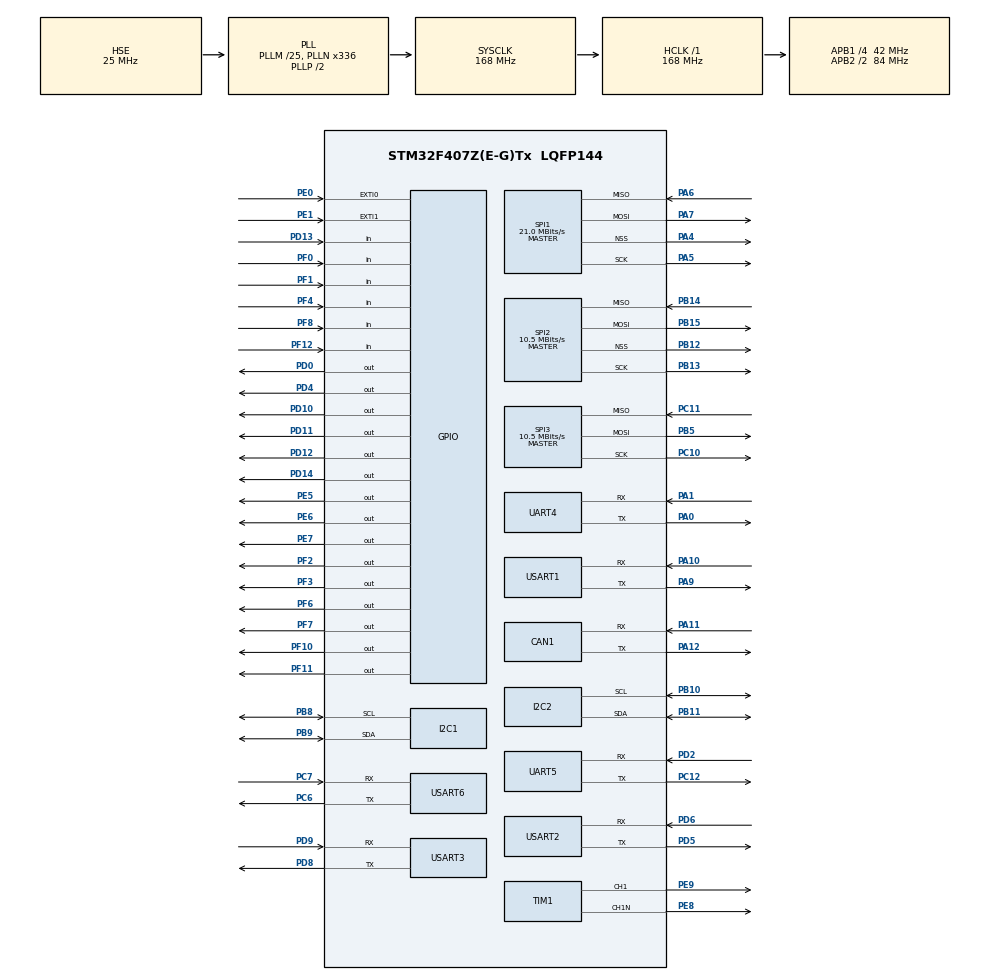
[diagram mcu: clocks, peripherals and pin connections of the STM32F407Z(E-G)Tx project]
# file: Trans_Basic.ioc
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CAN1.ABOM=ENABLE
CAN1.AWUM=ENABLE
CAN1.BS1=CAN_BS1_8TQ
CAN1.BS2=CAN_BS2_6TQ
CAN1.CalculateTimeQuantum=380.95238095238096
Dma.Request0=USART2_TX
Dma.USART2_TX.0.Direction=DMA_MEMORY_TO_PERIPH
Dma.USART2_TX.0.FIFOMode=DMA_FIFOMODE_DISABLE
Dma.USART2_TX.0.Instance=DMA1_Stream6
Dma.USART2_TX.0.MemDataAlignment=DMA_MDATAALIGN_BYTE
Dma.USART2_TX.0.MemInc=DMA_MINC_ENABLE
Dma.USART2_TX.0.Mode=DMA_NORMAL
Dma.USART2_TX.0.PeriphDataAlignment=DMA_PDATAALIGN_BYTE
Dma.USART2_TX.0.PeriphInc=DMA_PINC_DISABLE
Dma.USART2_TX.0.Priority=DMA_PRIORITY_LOW
I2C1.I2C_Mode=I2C_Fast
I2C1.OwnAddress=0x0A
I2C2.I2C_Mode=I2C_Fast
I2C2.OwnAddress=0x0A
Mcu.Family=STM32F4
Mcu.Name=STM32F407Z(E-G)Tx
Mcu.Package=LQFP144
NVIC.CAN1_RX0_IRQn=true\:2\:0\:true\:false\:true\:true
NVIC.DMA1_Stream6_IRQn=true\:0\:0\:false\:false\:true\:false
NVIC.EXTI0_IRQn=true\:0\:0\:false\:false\:true\:true
NVIC.EXTI1_IRQn=true\:0\:0\:false\:false\:true\:true
NVIC.PriorityGroup=NVIC_PRIORITYGROUP_4
NVIC.SPI1_IRQn=true\:1\:0\:true\:false\:true\:true
NVIC.SPI2_IRQn=true\:1\:0\:true\:false\:true\:true
NVIC.UART4_IRQn=true\:2\:0\:true\:false\:true\:true
NVIC.UART5_IRQn=true\:1\:0\:true\:false\:true\:true
NVIC.USART1_IRQn=true\:2\:0\:true\:false\:true\:true
NVIC.USART2_IRQn=true\:1\:0\:true\:false\:true\:true
NVIC.USART3_IRQn=true\:2\:0\:true\:false\:true\:true
PA0-WKUP.Mode=Asynchronous
PA0-WKUP.Signal=UART4_TX
PA1.Mode=Asynchronous
PA1.Signal=UART4_RX
PA10.Mode=Asynchronous
PA10.Signal=USART1_RX
PA11.Mode=Master
PA11.Signal=CAN1_RX
PA12.Mode=Master
PA12.Signal=CAN1_TX
PA13.Mode=JTAG_5_pins
PA13.Signal=SYS_JTMS-SWDIO
PA14.Mode=JTAG_5_pins
PA14.Signal=SYS_JTCK-SWCLK
PA15.Mode=JTAG_5_pins
PA15.Signal=SYS_JTDI
PA4.Mode=NSS_Signal_Hard_Output
PA4.Signal=SPI1_NSS
PA5.Mode=Full_Duplex_Master
PA5.Signal=SPI1_SCK
PA6.Mode=Full_Duplex_Master
PA6.Signal=SPI1_MISO
PA7.Mode=Full_Duplex_Master
PA7.Signal=SPI1_MOSI
PA9.Mode=Asynchronous
PA9.Signal=USART1_TX
PB10.Mode=I2C
PB10.Signal=I2C2_SCL
PB11.Mode=I2C
PB11.Signal=I2C2_SDA
PB12.Mode=NSS_Signal_Hard_Output
PB12.Signal=SPI2_NSS
PB13.Mode=Full_Duplex_Master
PB13.Signal=SPI2_SCK
PB14.Mode=Full_Duplex_Master
PB14.Signal=SPI2_MISO
PB15.Mode=Full_Duplex_Master
PB15.Signal=SPI2_MOSI
PB3.Mode=JTAG_5_pins
PB3.Signal=SYS_JTDO-SWO
PB4.Mode=JTAG_5_pins
PB4.Signal=SYS_JTRST
PB5.Mode=Full_Duplex_Master
PB5.Signal=SPI3_MOSI
PB8.Mode=I2C
PB8.Signal=I2C1_SCL
PB9.Mode=I2C
PB9.Signal=I2C1_SDA
PC10.Mode=Full_Duplex_Master
PC10.Signal=SPI3_SCK
PC11.Mode=Full_Duplex_Master
PC11.Signal=SPI3_MISO
PC12.Mode=Asynchronous
PC12.Signal=UART5_TX
PC6.Mode=Asynchronous
PC6.Signal=USART6_TX
PC7.Mode=Asynchronous
PC7.Signal=USART6_RX
PD0.GPIO_ModeDefaultOutputPP=GPIO_MODE_OUTPUT_PP
PD0.GPIO_PuPd=GPIO_NOPULL
PD0.GPIO_Speed=GPIO_SPEED_FREQ_LOW
PD0.PinState=GPIO_PIN_RESET
PD0.Signal=GPIO_Output
PD10.GPIO_Speed=GPIO_SPEED_FREQ_HIGH
PD10.Signal=GPIO_Output
PD11.PinState=GPIO_PIN_SET
PD11.Signal=GPIO_Output
PD12.PinState=GPIO_PIN_SET
PD12.Signal=GPIO_Output
PD13.GPIO_PuPd=GPIO_PULLUP
PD13.Signal=GPIO_Input
PD14.GPIO_PuPd=GPIO_NOPULL
PD14.Signal=GPIO_Output
PD2.Mode=Asynchronous
PD2.Signal=UART5_RX
PD4.Signal=GPIO_Output
PD5.Mode=Asynchronous
PD5.Signal=USART2_TX
PD6.Mode=Asynchronous
PD6.Signal=USART2_RX
PD8.Mode=Asynchronous
PD8.Signal=USART3_TX
PD9.Mode=Asynchronous
PD9.Signal=USART3_RX
PE0.Signal=GPXTI0
PE1.Signal=GPXTI1
PE5.GPIO_Speed=GPIO_SPEED_FREQ_HIGH
PE5.Signal=GPIO_Output
PE6.GPIO_Speed=GPIO_SPEED_FREQ_HIGH
PE6.Signal=GPIO_Output
PE7.Signal=GPIO_Output
PE8.Mode=PWM Generation1 CH1 CH1N
PE8.Signal=TIM1_CH1N
PE9.Signal=S_TIM1_CH1
PF0.GPIO_PuPd=GPIO_NOPULL
PF0.Signal=GPIO_Input
PF1.GPIO_PuPd=GPIO_NOPULL
PF1.Signal=GPIO_Input
PF10.Signal=GPIO_Output
PF11.Signal=GPIO_Output
PF12.GPIO_PuPd=GPIO_NOPULL
PF12.Signal=GPIO_Input
PF2.Signal=GPIO_Output
PF3.Signal=GPIO_Output
PF4.GPIO_PuPd=GPIO_NOPULL
PF4.Signal=GPIO_Input
PF6.Signal=GPIO_Output
PF7.Signal=GPIO_Output
PF8.GPIO_PuPd=GPIO_NOPULL
PF8.Signal=GPIO_Input
PH0-OSC_IN.Mode=HSE-External-Clock-Source
PH0-OSC_IN.Signal=RCC_OSC_IN
PH1-OSC_OUT.Mode=HSE-External-Clock-Source
PH1-OSC_OUT.Signal=RCC_OSC_OUT
ProjectManager.HeapSize=0x200
ProjectManager.StackSize=0x400
ProjectManager.TargetToolchain=MDK-ARM V5
RCC.48MHZClocksFreq_Value=84000000
RCC.AHBFreq_Value=168000000
RCC.APB1CLKDivider=RCC_HCLK_DIV4
RCC.APB1Freq_Value=42000000
RCC.APB1TimFreq_Value=84000000
RCC.APB2CLKDivider=RCC_HCLK_DIV2
RCC.APB2Freq_Value=84000000
RCC.APB2TimFreq_Value=168000000
RCC.CortexFreq_Value=168000000
RCC.EnbaleCSS=true
RCC.HCLKFreq_Value=168000000
RCC.HSE_VALUE=25000000
RCC.HSI_VALUE=16000000
RCC.LSE_VALUE=32768
RCC.PLLM=25
RCC.PLLN=336
RCC.PLLSourceVirtual=RCC_PLLSOURCE_HSE
RCC.SYSCLKFreq_VALUE=168000000
RCC.SYSCLKSource=RCC_SYSCLKSOURCE_PLLCLK
RCC.VCOOutputFreq_Value=336000000
SH.S_TIM1_CH1.0=TIM1_CH1,PWM Generation1 CH1 CH1N
SPI1.BaudRatePrescaler=SPI_BAUDRATEPRESCALER_4
SPI1.CLKPhase=SPI_PHASE_2EDGE
SPI1.CLKPolarity=SPI_POLARITY_HIGH
SPI1.CalculateBaudRate=21.0 MBits/s
SPI1.Direction=SPI_DIRECTION_2LINES
SPI1.Mode=SPI_MODE_MASTER
SPI1.VirtualNSS=VM_NSSHARD
SPI1.VirtualType=VM_MASTER
SPI2.BaudRatePrescaler=SPI_BAUDRATEPRESCALER_4
SPI2.CLKPhase=SPI_PHASE_2EDGE
SPI2.CLKPolarity=SPI_POLARITY_HIGH
SPI2.CalculateBaudRate=10.5 MBits/s
SPI2.Direction=SPI_DIRECTION_2LINES
SPI2.Mode=SPI_MODE_MASTER
SPI2.VirtualNSS=VM_NSSHARD
SPI2.VirtualType=VM_MASTER
SPI3.BaudRatePrescaler=SPI_BAUDRATEPRESCALER_4
SPI3.CLKPhase=SPI_PHASE_2EDGE
SPI3.CLKPolarity=SPI_POLARITY_HIGH
SPI3.CalculateBaudRate=10.5 MBits/s
SPI3.Direction=SPI_DIRECTION_2LINES
SPI3.Mode=SPI_MODE_MASTER
SPI3.VirtualType=VM_MASTER
TIM1.Channel-PWM\ Generation1\ CH1\ CH1N=TIM_CHANNEL_1
UART4.VirtualMode=Asynchronous
UART5.VirtualMode=Asynchronous
USART1.VirtualMode=VM_ASYNC
USART2.VirtualMode=VM_ASYNC
USART3.VirtualMode=VM_ASYNC
USART6.VirtualMode=VM_ASYNC
board=custom

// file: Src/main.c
/**
  ******************************************************************************
  * @file           : main.c
  * @brief          : Main program body
  ******************************************************************************
  ** This notice applies to any and all portions of this file
  * that are not between comment pairs USER CODE BEGIN and
  * USER CODE END. Other portions of this file, whether
  * inserted by the user or by software development tools
  * are owned by their respective copyright owners.
  *
  * COPYRIGHT(c) 2020 STMicroelectronics
  *
  * Redistribution and use in source and binary forms, with or without modification,
  * are permitted provided that the following conditions are met:
  *   1. Redistributions of source code must retain the above copyright notice,
  *      this list of conditions and the following disclaimer.
  *   2. Redistributions in binary form must reproduce the above copyright notice,
  *      this list of conditions and the following disclaimer in the documentation
  *      and/or other materials provided with the distribution.
  *   3. Neither the name of STMicroelectronics nor the names of its contributors
  *      may be used to endorse or promote products derived from this software
  *      without specific prior written permission.
  *
  * THIS SOFTWARE IS PROVIDED BY THE COPYRIGHT HOLDERS AND CONTRIBUTORS "AS IS"
  * AND ANY EXPRESS OR IMPLIED WARRANTIES, INCLUDING, BUT NOT LIMITED TO, THE
  * IMPLIED WARRANTIES OF MERCHANTABILITY AND FITNESS FOR A PARTICULAR PURPOSE ARE
  * DISCLAIMED. IN NO EVENT SHALL THE COPYRIGHT HOLDER OR CONTRIBUTORS BE LIABLE
  * FOR ANY DIRECT, INDIRECT, INCIDENTAL, SPECIAL, EXEMPLARY, OR CONSEQUENTIAL
  * DAMAGES (INCLUDING, BUT NOT LIMITED TO, PROCUREMENT OF SUBSTITUTE GOODS OR
  * SERVICES; LOSS OF USE, DATA, OR PROFITS; OR BUSINESS INTERRUPTION) HOWEVER
  * CAUSED AND ON ANY THEORY OF LIABILITY, WHETHER IN CONTRACT, STRICT LIABILITY,
  * OR TORT (INCLUDING NEGLIGENCE OR OTHERWISE) ARISING IN ANY WAY OUT OF THE USE
  * OF THIS SOFTWARE, EVEN IF ADVISED OF THE POSSIBILITY OF SUCH DAMAGE.
  *
  ******************************************************************************
  */
#include "main.h"
#include "stm32f4xx_hal.h"
#include "can.h"
#include "dma.h"
#include "i2c.h"
#include "spi.h"
#include "tim.h"
#include "usart.h"
#include "gpio.h"

/* USER CODE BEGIN PV */
/* Private variables ---------------------------------------------------------*/

  uint16_t freq_divide;      //分频系数

/* USER CODE END PV */

void SystemClock_Config(void);

/* USER CODE BEGIN PFP */
/* Private function prototypes -----------------------------------------------*/

/* USER CODE END PFP */

int main(void)
{

  /* MCU Configuration----------------------------------------------------------*/

  /* Reset of all peripherals, Initializes the Flash interface and the Systick. */
  HAL_Init();

  /* Configure the system clock */
  SystemClock_Config();

  /* Initialize all configured peripherals */
  MX_GPIO_Init();
  MX_DMA_Init();
  MX_CAN1_Init();
  MX_I2C1_Init();
  MX_I2C2_Init();
  MX_SPI1_Init();
  MX_SPI2_Init();
  MX_SPI3_Init();
  MX_TIM1_Init();
  MX_UART4_Init();
  MX_UART5_Init();
  MX_USART1_UART_Init();
  MX_USART2_UART_Init();
  MX_USART3_UART_Init();
  MX_USART6_UART_Init();
  /* USER CODE BEGIN 2 */

//  //开启频率
//  HAL_TIM_Base_Start_IT(&htim1);
//  HAL_TIM_OC_Start_IT(&htim1,TIM_CHANNEL_1);
//  freq_divide=1999;                                                               //起始分频为1999+1=2000，168Mhz/2000=84Khz
//  TIM1->ARR=freq_divide;                                                          //ARR:TIM auto-reload register
//  htim1.Instance->CCR1=freq_divide/2;                                             //占空比50%

  /* USER CODE END 2 */

  /* Infinite loop */
  while (1)
  {

  }

}

void SystemClock_Config(void)
{

  RCC_OscInitTypeDef RCC_OscInitStruct;
  RCC_ClkInitTypeDef RCC_ClkInitStruct;

    /**Configure the main internal regulator output voltage
    */
  __HAL_RCC_PWR_CLK_ENABLE();

  __HAL_PWR_VOLTAGESCALING_CONFIG(PWR_REGULATOR_VOLTAGE_SCALE1);

    /**Initializes the CPU, AHB and APB busses clocks
    */
  RCC_OscInitStruct.OscillatorType = RCC_OSCILLATORTYPE_HSE;
  RCC_OscInitStruct.HSEState = RCC_HSE_BYPASS;
  RCC_OscInitStruct.PLL.PLLState = RCC_PLL_ON;
  RCC_OscInitStruct.PLL.PLLSource = RCC_PLLSOURCE_HSE;
  RCC_OscInitStruct.PLL.PLLM = 25;
  RCC_OscInitStruct.PLL.PLLN = 336;
  RCC_OscInitStruct.PLL.PLLP = RCC_PLLP_DIV2;
  RCC_OscInitStruct.PLL.PLLQ = 4;
  if (HAL_RCC_OscConfig(&RCC_OscInitStruct) != HAL_OK)
  {
    _Error_Handler(__FILE__, __LINE__);
  }

    /**Initializes the CPU, AHB and APB busses clocks
    */
  RCC_ClkInitStruct.ClockType = RCC_CLOCKTYPE_HCLK|RCC_CLOCKTYPE_SYSCLK
                              |RCC_CLOCKTYPE_PCLK1|RCC_CLOCKTYPE_PCLK2;
  RCC_ClkInitStruct.SYSCLKSource = RCC_SYSCLKSOURCE_PLLCLK;
  RCC_ClkInitStruct.AHBCLKDivider = RCC_SYSCLK_DIV1;
  RCC_ClkInitStruct.APB1CLKDivider = RCC_HCLK_DIV4;
  RCC_ClkInitStruct.APB2CLKDivider = RCC_HCLK_DIV2;

  if (HAL_RCC_ClockConfig(&RCC_ClkInitStruct, FLASH_LATENCY_5) != HAL_OK)
  {
    _Error_Handler(__FILE__, __LINE__);
  }

    /**Enables the Clock Security System
    */
  HAL_RCC_EnableCSS();

    /**Configure the Systick interrupt time
    */
  HAL_SYSTICK_Config(HAL_RCC_GetHCLKFreq()/1000);

    /**Configure the Systick
    */
  HAL_SYSTICK_CLKSourceConfig(SYSTICK_CLKSOURCE_HCLK);

  /* SysTick_IRQn interrupt configuration */
  HAL_NVIC_SetPriority(SysTick_IRQn, 0, 0);
}

void _Error_Handler(char *file, int line)
{
  while(1)
  {
  }
}

/************************ (C) COPYRIGHT STMicroelectronics *****END OF FILE****/
